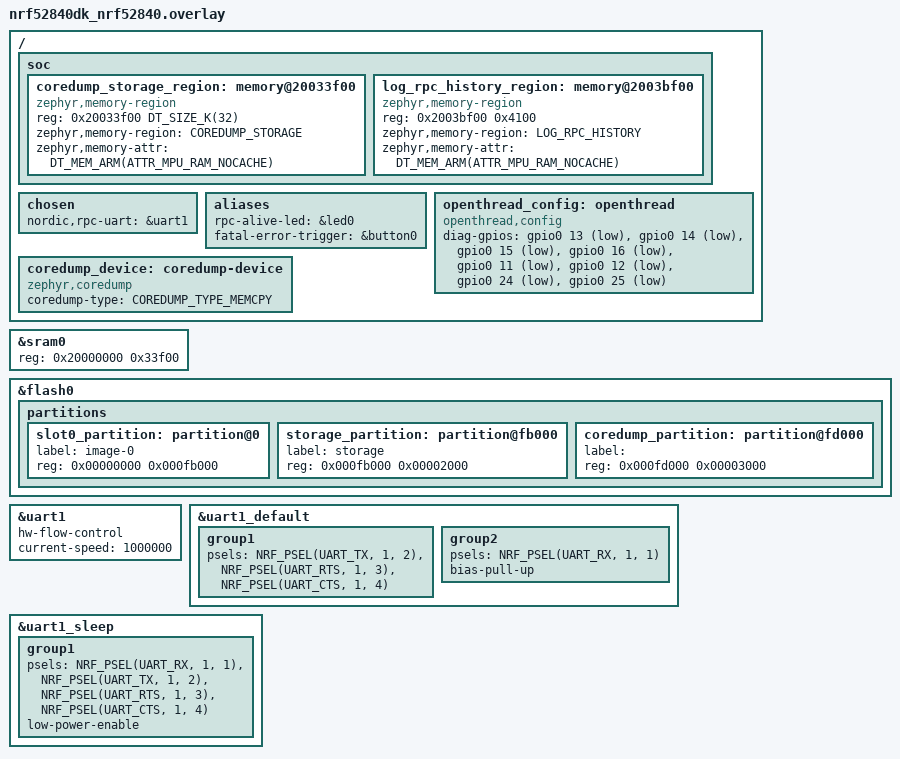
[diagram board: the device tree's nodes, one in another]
/*
 * Copyright (c) 2024 Nordic Semiconductor ASA
 *
 * SPDX-License-Identifier: LicenseRef-Nordic-5-Clause
 */
#include <zephyr/dt-bindings/memory-attr/memory-attr-arm.h>

/* Log RPC history + optional RAM coredump. */
/ {
	soc {
		coredump_storage_region: memory@20033f00 {
			compatible = "zephyr,memory-region", "mmio-sram";
			reg = <0x20033f00 DT_SIZE_K(32)>;
			zephyr,memory-region = "COREDUMP_STORAGE";
			zephyr,memory-attr = <DT_MEM_ARM(ATTR_MPU_RAM_NOCACHE)>;
			status = "okay";
		};

		/* 0x4100 = 0x4000 buffer + 0x100 control; ends at 0x20040000 */
		log_rpc_history_region: memory@2003bf00 {
			compatible = "zephyr,memory-region", "mmio-sram";
			reg = <0x2003bf00 0x4100>;
			zephyr,memory-region = "LOG_RPC_HISTORY";
			zephyr,memory-attr = <DT_MEM_ARM(ATTR_MPU_RAM_NOCACHE)>;
			status = "okay";
		};
	};
};

/* Shorter sram0 (0x33f00); 32 KiB COREDUMP_STORAGE; top 0x4100 = log history. */
&sram0 {
	reg = <0x20000000 0x33f00>;
};

/ {
	chosen {
		nordic,rpc-uart = &uart1;
	};

	aliases {
		rpc-alive-led = &led0;
		fatal-error-trigger = &button0;
	};

	openthread_config: openthread {
		compatible = "openthread,config";
		diag-gpios = <&gpio0 13 GPIO_ACTIVE_LOW>,
			     <&gpio0 14 GPIO_ACTIVE_LOW>,
			     <&gpio0 15 GPIO_ACTIVE_LOW>,
			     <&gpio0 16 GPIO_ACTIVE_LOW>,
			     <&gpio0 11 (GPIO_PULL_UP | GPIO_ACTIVE_LOW)>,
			     <&gpio0 12 (GPIO_PULL_UP | GPIO_ACTIVE_LOW)>,
			     <&gpio0 24 (GPIO_PULL_UP | GPIO_ACTIVE_LOW)>,
			     <&gpio0 25 (GPIO_PULL_UP | GPIO_ACTIVE_LOW)>;
	};

	coredump_device: coredump-device {
		compatible = "zephyr,coredump";
		coredump-type = "COREDUMP_TYPE_MEMCPY";
		status = "okay";
	};
};

/delete-node/ &boot_partition;
/delete-node/ &slot0_partition;
/delete-node/ &slot1_partition;
/delete-node/ &storage_partition;

&flash0 {
	partitions {
		slot0_partition: partition@0 {
			label = "image-0";
			reg = <0x00000000 0x000fb000>;
		};

		storage_partition: partition@fb000 {
			label = "storage";
			reg = <0x000fb000 0x00002000>;
		};

		coredump_partition: partition@fd000 {
			label = "";
			reg = <0x000fd000 0x00003000>;
		};
	};
};

&uart1 {
	status = "okay";
	hw-flow-control;
	current-speed = <1000000>;
};

&uart1_default {
	group1 {
		psels = <NRF_PSEL(UART_TX, 1, 2)>,
			<NRF_PSEL(UART_RTS, 1, 3)>,
			<NRF_PSEL(UART_CTS, 1, 4)>;
	};

	group2 {
		psels = <NRF_PSEL(UART_RX, 1, 1)>;
		bias-pull-up;
	};
};

&uart1_sleep {
	group1 {
		psels = <NRF_PSEL(UART_RX, 1, 1)>,
			<NRF_PSEL(UART_TX, 1, 2)>,
			<NRF_PSEL(UART_RTS, 1, 3)>,
			<NRF_PSEL(UART_CTS, 1, 4)>;
		low-power-enable;
	};
};
